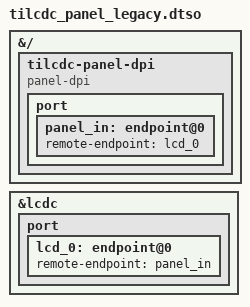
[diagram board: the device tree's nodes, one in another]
// SPDX-License-Identifier: GPL-2.0+
/*
 * DTS overlay for converting ti,tilcdc,panel binding to new binding.
 *
 * Copyright (C) 2025 Bootlin
 * Author: Kory Maincent <kory.maincent@bootlin.com>
 */

/dts-v1/;
/plugin/;

&{/} {
	tilcdc-panel-dpi {
		compatible = "panel-dpi";
		port {
			panel_in: endpoint@0 {
				remote-endpoint = <&lcd_0>;
			};
		};
	};
};

&lcdc {
	port {
		lcd_0: endpoint@0 {
			remote-endpoint = <&panel_in>;
		};
	};
};
